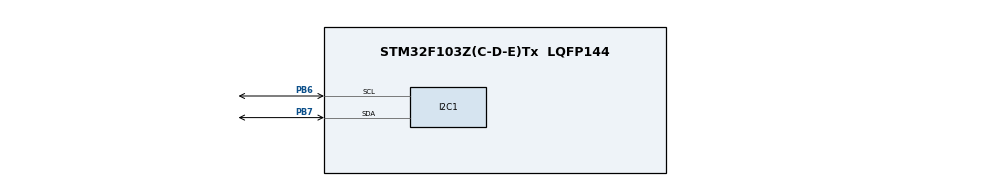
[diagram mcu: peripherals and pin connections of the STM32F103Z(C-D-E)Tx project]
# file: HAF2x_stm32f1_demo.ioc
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I2C1.I2C_Mode=I2C_Standard
I2C1.OwnAddress=72
Mcu.Family=STM32F1
Mcu.Name=STM32F103Z(C-D-E)Tx
Mcu.Package=LQFP144
NVIC.PriorityGroup=NVIC_PRIORITYGROUP_4
OSC_IN.Mode=HSE-External-Oscillator
OSC_IN.Signal=RCC_OSC_IN
OSC_OUT.Mode=HSE-External-Oscillator
OSC_OUT.Signal=RCC_OSC_OUT
PA13.Mode=Serial_Wire
PA13.Signal=SYS_JTMS-SWDIO
PA14.Mode=Serial_Wire
PA14.Signal=SYS_JTCK-SWCLK
PB6.Mode=I2C
PB6.Signal=I2C1_SCL
PB7.Mode=I2C
PB7.Signal=I2C1_SDA
ProjectManager.HeapSize=0x200
ProjectManager.StackSize=0x400
ProjectManager.TargetToolchain=EWARM V8.32
RCC.APB1Freq_Value=8000000
RCC.APB2Freq_Value=8000000
board=custom

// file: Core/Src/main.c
/* USER CODE BEGIN Header */
/**
  ******************************************************************************
  * @file           : main.c
  * @brief          : Main program body
  ******************************************************************************
  * @attention
  *
  * <h2><center>&copy; Copyright (c) 2022 STMicroelectronics.
  * All rights reserved.</center></h2>
  *
  * This software component is licensed by ST under BSD 3-Clause license,
  * the "License"; You may not use this file except in compliance with the
  * License. You may obtain a copy of the License at:
  *                        opensource.org/licenses/BSD-3-Clause
  *
  ******************************************************************************
  */
/* USER CODE END Header */
#include "main.h"
#include "i2c.h"
#include "gpio.h"

/* USER CODE BEGIN Includes */
#include <stdio.h>
#include "HAF.h"
#include "Port.h"
/* USER CODE END Includes */

void SystemClock_Config(void);

int main(void)
{
  /* USER CODE BEGIN 1 */
  HafSensorConfig senssor = {0};

  /* USER CODE END 1 */

  /* MCU Configuration--------------------------------------------------------*/

  /* Reset of all peripherals, Initializes the Flash interface and the Systick. */
  HAL_Init();

  /* Configure the system clock */
  SystemClock_Config();

  /* Initialize all configured peripherals */
  MX_GPIO_Init();
  MX_I2C1_Init();
  /* USER CODE BEGIN 2 */
  // put your setup code here, to run once:
  senssor.i2cAddress = 0x48;
  Port_I2cInit();
  printf("The driver version is V%d.%02d\r\n",MAJOR_VERSION,MINOR_VERSION);
  printf("I2c init OK!\r\n");
  //suggest warm up time
  HAL_Delay(50);

  /*********************get serial number**********************/
  while (HAF_GetSn(senssor.i2cAddress, senssor.sn) != 0)
  {
    printf("Get sn error!\r\n");
    HAL_Delay(1000);
  }
  printf("SN: %02X%02X%02X%02X\r\n",senssor.sn[0],senssor.sn[1],senssor.sn[2],senssor.sn[3]);

  /********************get flow min and max********************/
  while (HAF_GetFlowMin(senssor.i2cAddress, &senssor.flowMin) != 0)
  {
    printf("Get flowMin error!\r\n");
    HAL_Delay(1000);
  }
  while (HAF_GetFlowMax(senssor.i2cAddress, &senssor.flowMax) != 0)
  {
    printf("Get flowMax error!\r\n");
    HAL_Delay(1000);
  }
  printf("Flow min: %d\r\n", senssor.flowMin);
  printf("Flow max: %d\r\n", senssor.flowMax);

  /**************************get unit**************************/
  if (HAF_GetUnit(senssor.i2cAddress, &senssor.flowUnit) != 0)
  {
    printf("Get unit error!\r\n");
  }
  else
  {
    if (senssor.flowUnit == HAF_UNIT_SCCM)
	  printf("Unit: sccm\r\n");
    else if (senssor.flowUnit == HAF_UNIT_SLM)
	  printf("Unit: slm\r\n");
  }

  /**************************set gas type**********************/
  if (HAF_SetGasType(senssor.i2cAddress, HAF_GAS_TYPE_AIR) != 0)
  {
    printf("Set gas type error!\r\n");
  }
  else
  {
    printf("Set gas type successfully!\r\n");
  }

  /*********************set gas proportion**********************/
  if (HAF_SetGasProportion(senssor.i2cAddress, 100) != 0)
  {
    printf("Set gas proportion error!\r\n");
  }
  else
  {
    printf("Set gas proportion successfully!\r\n");
  }

  /*********************get gas type***************************/
  if (HAF_GetGasType(senssor.i2cAddress, &senssor.gasType) != 0)
  {
    printf("Get gas type error!\r\n");
  }
  else
  {
    if (senssor.gasType == HAF_GAS_TYPE_AIR)
	  printf("Gas type: Air\r\n");
    else if (senssor.gasType == HAF_GAS_TYPE_O2)
	  printf("Gas type: O2\r\n");
    else if (senssor.gasType == HAF_GAS_TYPE_N2O)
	  printf("Gas type: N2O\r\n");
    else if (senssor.gasType == HAF_GAS_TYPE_O2_AIR)
	  printf("Gas type: O2&Air\r\n");
    else if (senssor.gasType == HAF_GAS_TYPE_N2O_AIR)
	  printf("Gas type: N2O&Air\r\n");
    else if (senssor.gasType == HAF_GAS_TYPE_O2_N2O)
	  printf("Gas type: O2&N2O\r\n");
  }

  /*********************get gas proportion**********************/
  if (HAF_GetGasProportion(senssor.i2cAddress, &senssor.gasProportion) != 0)
  {
    printf("Get gas proportion error!\r\n");
  }
  else
  {
    printf("Gas proportion: %d%\r\n", senssor.gasProportion);
  }

  /* USER CODE END 2 */

  /* Infinite loop */
  while (1)
  {

    /* USER CODE BEGIN 3 */
    // put your main code here, to run repeatedly:
    /*********************get flow and temp**********************/
    if (HAF_GetFlowTemp(senssor.i2cAddress, &senssor.flow, &senssor.temp) != 0)
    {
      printf("Get flow and temp error!");
    }
    else
    {
      float flow = (senssor.flowMax - senssor.flowMin) * ((float)senssor.flow / 65535 - 0.1) / 0.8 + senssor.flowMin;
  	  if (senssor.flowUnit == HAF_UNIT_SCCM)
        printf("Flow: %.3fsccm", flow);
	  else if (senssor.flowUnit == HAF_UNIT_SLM)
        printf("Flow: %.3fslm", flow);
      printf("   Temp: %.1f��\r\n",(float)senssor.temp / 100);
    }
    HAL_Delay(1000);
  }
  /* USER CODE END 3 */
}

void SystemClock_Config(void)
{
  RCC_OscInitTypeDef RCC_OscInitStruct = {0};
  RCC_ClkInitTypeDef RCC_ClkInitStruct = {0};

  /** Initializes the RCC Oscillators according to the specified parameters
  * in the RCC_OscInitTypeDef structure.
  */
  RCC_OscInitStruct.OscillatorType = RCC_OSCILLATORTYPE_HSI;
  RCC_OscInitStruct.HSIState = RCC_HSI_ON;
  RCC_OscInitStruct.HSICalibrationValue = RCC_HSICALIBRATION_DEFAULT;
  RCC_OscInitStruct.PLL.PLLState = RCC_PLL_NONE;
  if (HAL_RCC_OscConfig(&RCC_OscInitStruct) != HAL_OK)
  {
    Error_Handler();
  }
  /** Initializes the CPU, AHB and APB buses clocks
  */
  RCC_ClkInitStruct.ClockType = RCC_CLOCKTYPE_HCLK|RCC_CLOCKTYPE_SYSCLK
                              |RCC_CLOCKTYPE_PCLK1|RCC_CLOCKTYPE_PCLK2;
  RCC_ClkInitStruct.SYSCLKSource = RCC_SYSCLKSOURCE_HSI;
  RCC_ClkInitStruct.AHBCLKDivider = RCC_SYSCLK_DIV1;
  RCC_ClkInitStruct.APB1CLKDivider = RCC_HCLK_DIV1;
  RCC_ClkInitStruct.APB2CLKDivider = RCC_HCLK_DIV1;

  if (HAL_RCC_ClockConfig(&RCC_ClkInitStruct, FLASH_LATENCY_0) != HAL_OK)
  {
    Error_Handler();
  }
}

void Error_Handler(void)
{
  __disable_irq();
  while (1)
  {
  }
}

/************************ (C) COPYRIGHT STMicroelectronics *****END OF FILE****/
